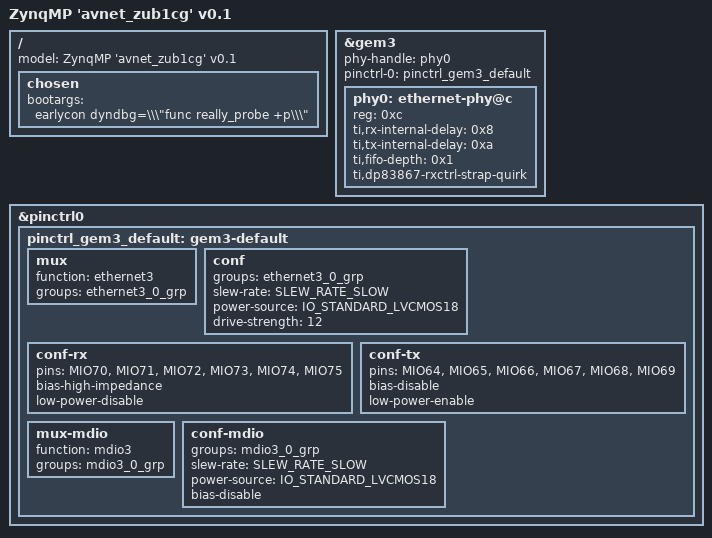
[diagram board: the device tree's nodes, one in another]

#include "include/dt-bindings/pinctrl/pinctrl-zynqmp.h"

/ {
    
    model = "ZynqMP 'avnet_zub1cg' v0.1";
	chosen {
        bootargs = "earlycon dyndbg=\\\"func really_probe +p\\\"";
	};    
};

/* Enable GEM3 for PS-enabled ethernet access */

&gem3 {
	phy-handle = <&phy0>;
	pinctrl-names = "default";
	pinctrl-0 = <&pinctrl_gem3_default>;
	phy0: ethernet-phy@c {
		reg = <0xc>;
		ti,rx-internal-delay = <0x8>;
		ti,tx-internal-delay = <0xa>;
		ti,fifo-depth = <0x1>;
		ti,dp83867-rxctrl-strap-quirk;
	};
};

/* Enable pins for GEM3 */

&pinctrl0 {
	status = "okay";

	pinctrl_gem3_default: gem3-default {
		mux {
			function = "ethernet3";
			groups = "ethernet3_0_grp";
		};

		conf {
			groups = "ethernet3_0_grp";
			slew-rate = <SLEW_RATE_SLOW>;
			power-source = <IO_STANDARD_LVCMOS18>;
			drive-strength = <12>;
		};

		conf-rx {
			pins = "MIO70", "MIO71", "MIO72", "MIO73", "MIO74",
									"MIO75";
			bias-high-impedance;
			low-power-disable;
		};

		conf-tx {
			pins = "MIO64", "MIO65", "MIO66", "MIO67", "MIO68",
									"MIO69";
			bias-disable;
			low-power-enable;
		};

		mux-mdio {
			function = "mdio3";
			groups = "mdio3_0_grp";
		};

		conf-mdio {
			groups = "mdio3_0_grp";
			slew-rate = <SLEW_RATE_SLOW>;
			power-source = <IO_STANDARD_LVCMOS18>;
			bias-disable;
		};
	};
};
